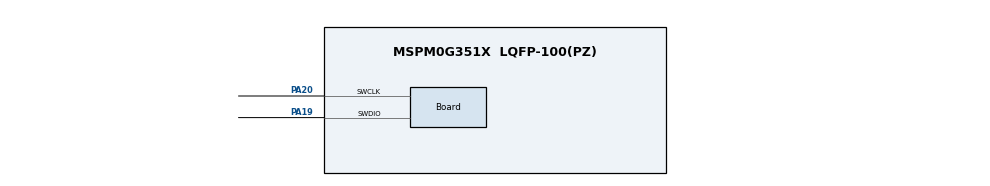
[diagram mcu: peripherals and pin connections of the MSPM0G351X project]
/**
 * @cliArgs --device "MSPM0G351X" --part "Default" --package "LQFP-100(PZ)" --product "mspm0_sdk@2.09.00.02"
 * @versions {"tool":"1.25.0+4268"}
 */

/**
 * Import the modules used in this configuration.
 */
const Board         = scripting.addModule("/ti/driverlib/Board");
const SYSCTL        = scripting.addModule("/ti/driverlib/SYSCTL");
const ProjectConfig = scripting.addModule("/ti/project_config/ProjectConfig");

/**
 * Write custom configuration values to the imported modules.
 */
Board.peripheral.$assign          = "DEBUGSS";
Board.peripheral.swclkPin.$assign = "PA20";
Board.peripheral.swdioPin.$assign = "PA19";

SYSCTL.forceDefaultClkConfig = true;
SYSCTL.clockTreeEn           = true;

ProjectConfig.migrationCondition = true;
ProjectConfig.genLibDrivers      = true;
